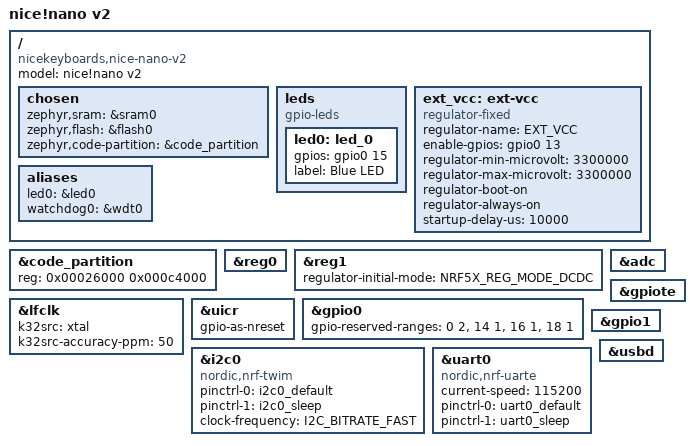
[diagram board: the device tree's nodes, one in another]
/*
 * Copyright (c) 2026 Wafer Pad contributors
 * SPDX-License-Identifier: Apache-2.0
 *
 * nice!nano v2 (Nordic nRF52840, Pro Micro footprint) with the factory
 * Adafruit nRF52 UF2 bootloader. Out-of-tree board: upstream Zephyr v4.5.0
 * has no nice!nano board (ZMK ships one in its own Zephyr fork).
 *
 * Hardware facts below were checked against the nice!nano v2 schematic
 * (nicekeyboards.com/docs/nice-nano) — see docs/wiring.md for details.
 */

/dts-v1/;
#include <nordic/nrf52840_qiaa.dtsi>
#include <nordic/nrf52840_partition_uf2_sdv6.dtsi>
#include "nice_nano_v2-pinctrl.dtsi"

/ {
	model = "nice!nano v2";
	compatible = "nicekeyboards,nice-nano-v2";

	chosen {
		zephyr,sram = &sram0;
		zephyr,flash = &flash0;
		zephyr,code-partition = &code_partition;
	};

	leds {
		compatible = "gpio-leds";

		/* Schematic net BLED on P0.15, active high (bootloader board.h:
		 * LED_PRIMARY_PIN P0.15, LED_STATE_ON 1). */
		led0: led_0 {
			gpios = <&gpio0 15 GPIO_ACTIVE_HIGH>;
			label = "Blue LED";
		};
	};

	/*
	 * "VCC"/3V3 header pin: U3 = XC6220B331MR 3.3 V LDO fed from VDDH.
	 * Its CE pin is net POWER_PIN = P0.13 with a 10 MOhm pull-up to VDDH:
	 * the rail is ON by default and only switches OFF when P0.13 is driven
	 * low. The TPS65 and the LSM6DSOX are powered from this rail.
	 *
	 * Wafer Pad v0.1 keeps it permanently on (regulator-always-on): the
	 * firmware never cuts sensor power. It also stays on in System OFF
	 * (GPIO output latch retained) so that the trackpad can wake the MCU.
	 */
	ext_vcc: ext-vcc {
		compatible = "regulator-fixed";
		regulator-name = "EXT_VCC";
		enable-gpios = <&gpio0 13 GPIO_ACTIVE_HIGH>;
		regulator-min-microvolt = <3300000>;
		regulator-max-microvolt = <3300000>;
		regulator-boot-on;
		regulator-always-on;
		startup-delay-us = <10000>;
	};

	aliases {
		led0 = &led0;
		watchdog0 = &wdt0;
	};
};

/*
 * Flash map (nrf52840_partition_uf2_sdv6.dtsi + one change):
 *   0x00000-0x26000  MBR + SoftDevice S140 v6.1.1 (kept, read-only)
 *   0x26000-0xEA000  application (784 KB)
 *   0xEC000-0xF4000  storage (settings / BLE bonds, 32 KB)
 *   0xF4000-0x100000 UF2 bootloader + its settings (read-only)
 * The Adafruit bootloader only accepts UF2 blocks below
 * USER_FLASH_END = 0xF4000 - DFU_APP_DATA_RESERVED (40 KB) = 0xEA000, so the
 * upstream 0xC6000-byte code partition is shrunk to end at 0xEA000 to make
 * the linker enforce the real limit.
 */
&code_partition {
	reg = <0x00026000 0x000c4000>;
};

/* REG0 (VDDH -> VDD) DC/DC: L1 10 uH on DCCH is fitted. */
&reg0 {
	status = "okay";
};

/* REG1 (VDD -> 1V3) DC/DC: L3 15 nH + L4 10 uH on DCC are fitted. */
&reg1 {
	regulator-initial-mode = <NRF5X_REG_MODE_DCDC>;
};

/* 32.768 kHz crystal Y2 (FC-12M) on XL1/XL2 = P0.00/P0.01. */
&lfclk {
	k32src = "xtal";
	k32src-accuracy-ppm = <50>;
};

&uicr {
	gpio-as-nreset;
};

&adc {
	status = "okay";
};

&gpiote {
	status = "okay";
};

&gpio0 {
	status = "okay";
	/* P0.00/P0.01: 32 kHz crystal. P0.14, P0.16: tied to the RESET net on the
	 * v2 schematic. P0.18: nRESET. Never use these as GPIO. */
	gpio-reserved-ranges = <0 2>, <14 1>, <16 1>, <18 1>;
};

&gpio1 {
	status = "okay";
};

&i2c0 {
	compatible = "nordic,nrf-twim";
	pinctrl-0 = <&i2c0_default>;
	pinctrl-1 = <&i2c0_sleep>;
	pinctrl-names = "default", "sleep";
	clock-frequency = <I2C_BITRATE_FAST>;
	/* Left disabled: the application overlay enables it and adds devices. */
};

&uart0 {
	compatible = "nordic,nrf-uarte";
	current-speed = <115200>;
	pinctrl-0 = <&uart0_default>;
	pinctrl-1 = <&uart0_sleep>;
	pinctrl-names = "default", "sleep";
};

zephyr_udc0: &usbd {
	status = "okay";
};

#include <../boards/common/usb/cdc_acm_serial.dtsi>
